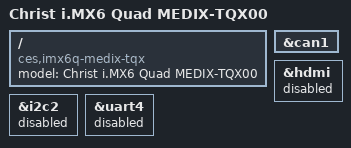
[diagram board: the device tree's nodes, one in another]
// SPDX-License-Identifier: GPL-2.0
/*
 * Copyright (C) 2018-2023 Christ Electronic Systems GmbH
 * Peter Fink <pfink@christ-es.de>
 * Copyright 2012-2015 Freescale Semiconductor, Inc.
 * Copyright 2011 Linaro Ltd.
 *
 * The code contained herein is licensed under the GNU General Public
 * License. You may obtain a copy of the GNU General Public License
 * Version 2 or later at the following locations:
 *
 * http://www.opensource.org/licenses/gpl-license.html
 * http://www.gnu.org/copyleft/gpl.html
 */

/dts-v1/;

#include "imx6q.dtsi"
#include "imx6qdl-medix-x.dtsi"

/ {
	model = "Christ i.MX6 Quad MEDIX-TQX00";
	compatible = "ces,imx6q-medix-tqx", "fsl,imx6q";
};

&can1 {
	status = "okay";
};

&hdmi {
	status = "disabled";
};

&i2c2 {
	status = "disabled";
};

&uart4 {
	status = "disabled";
};
